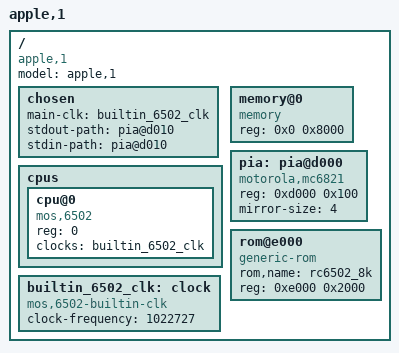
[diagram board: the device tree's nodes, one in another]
#include <generic-pia.h>

/dts-v1/;

/ {
	compatible = "apple,1", "mos,6502";
	model = "apple,1";
	#address-cells = <1>;
	#size-cells = <1>;

	chosen {
		main-clk = <&builtin_6502_clk>;
		stdout-path = "pia@d010";
		stdin-path = "pia@d010";
	};

	cpus {
		#address-cells = <1>;
		#size-cells = <0>;
		cpu@0 {
			device_type = "cpu";
			compatible = "mos,6502";
			reg = <0>;
			clocks = <&builtin_6502_clk>;
			//dtemu,override-reset-vector = <0xff00>;
		};
	};
	
	builtin_6502_clk: clock {
		compatible = "mos,6502-builtin-clk","fixed-clock";
		#clock-cells = <0>;
		clock-frequency = <1022727>;
	};

	memory@0 {
		compatible = "memory";
		reg = <0x0 0x8000>;
	};

	pia: pia@d000 {
//		gpio-controller;
//		#gpio-cells = <1>;
		compatible = "motorola,mc6821";
		reg = <0xd000 0x100>;
		mirror-size = <4>;
	};

//	keyboard {
//		compatible = "apple,apple1-keyboard";
//		key-gpios = <&pia PA0>, <&pia PA1>,
//			<&pia PA2>, <&pia PA3>,
//			<&pia PA4>, <&pia PA5>,
//			<&pia PA6>, <&pia PA7>;
//		strobe-gpios = <&pia CA1>;
//	};

//	display {
//		compatible = "apple,apple1-display";
//		char-gpios = <&pia PB0>, <&pia PB1>,
//			<&pia PB2>, <&pia PB3>,
//			<&pia PB4>, <&pia PB5>,
//			<&pia PB6>;
//		rda-gpios = <&pia CB1>;
//		da-gpios = <&pia CB2>, <&pia PB7>;
//	};

	rom@e000 {
		compatible = "generic-rom";
		rom,name = "rc6502_8k";
		reg = <0xe000 0x2000>;
	};
};
